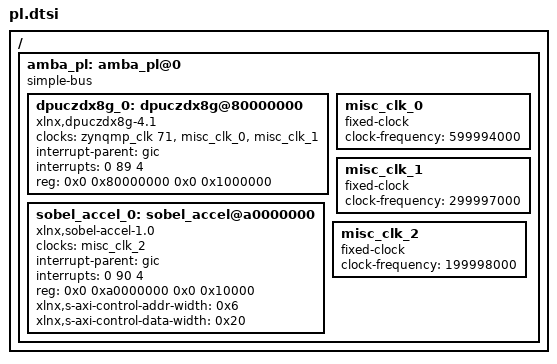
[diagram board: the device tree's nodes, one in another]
/*
 * CAUTION: This file is automatically generated by Xilinx.
 * Version: XSCT 
 * Today is: Tue Sep 15 23:19:41 2026
 */


/ {
	amba_pl: amba_pl@0 {
		#address-cells = <2>;
		#size-cells = <2>;
		compatible = "simple-bus";
		ranges ;
		dpuczdx8g_0: dpuczdx8g@80000000 {
			clock-names = "s_axi_aclk", "dpu_2x_clk", "m_axi_dpu_aclk";
			clocks = <&zynqmp_clk 71>, <&misc_clk_0>, <&misc_clk_1>;
			compatible = "xlnx,dpuczdx8g-4.1";
			interrupt-names = "dpu0_interrupt";
			interrupt-parent = <&gic>;
			interrupts = <0 89 4>;
			reg = <0x0 0x80000000 0x0 0x1000000>;
		};
		misc_clk_0: misc_clk_0 {
			#clock-cells = <0>;
			clock-frequency = <599994000>;
			compatible = "fixed-clock";
		};
		misc_clk_1: misc_clk_1 {
			#clock-cells = <0>;
			clock-frequency = <299997000>;
			compatible = "fixed-clock";
		};
		sobel_accel_0: sobel_accel@a0000000 {
			clock-names = "ap_clk";
			clocks = <&misc_clk_2>;
			compatible = "xlnx,sobel-accel-1.0";
			interrupt-names = "interrupt";
			interrupt-parent = <&gic>;
			interrupts = <0 90 4>;
			reg = <0x0 0xa0000000 0x0 0x10000>;
			xlnx,s-axi-control-addr-width = <0x6>;
			xlnx,s-axi-control-data-width = <0x20>;
		};
		misc_clk_2: misc_clk_2 {
			#clock-cells = <0>;
			clock-frequency = <199998000>;
			compatible = "fixed-clock";
		};
	};
};
